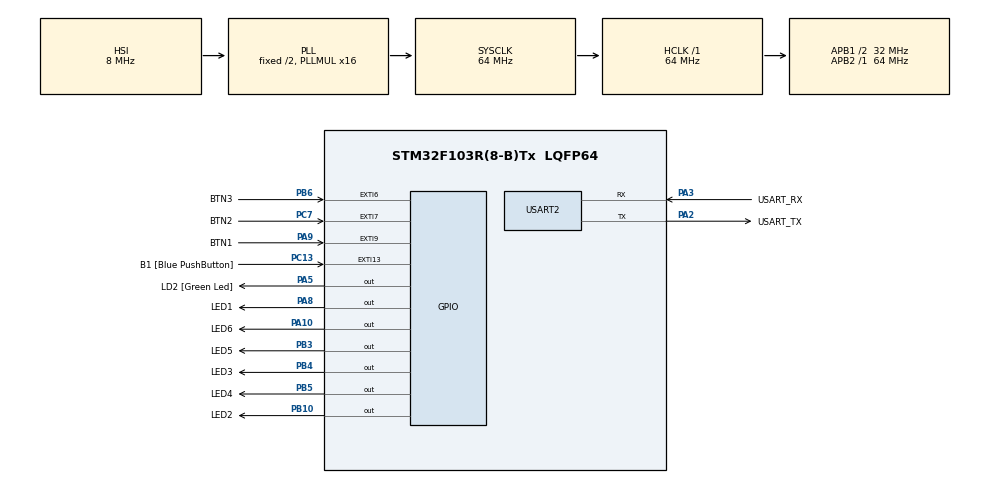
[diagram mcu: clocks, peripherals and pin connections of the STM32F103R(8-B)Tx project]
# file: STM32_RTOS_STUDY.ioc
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FREERTOS.Tasks01=defaultTask,24,128,StartDefaultTask,Default,NULL,Dynamic,NULL,NULL
FREERTOS.configTOTAL_HEAP_SIZE=10240
Mcu.Family=STM32F1
Mcu.Name=STM32F103R(8-B)Tx
Mcu.Package=LQFP64
NVIC.EXTI15_10_IRQn=true\:5\:0\:false\:false\:true\:true\:true\:true\:true
NVIC.EXTI9_5_IRQn=true\:5\:0\:false\:false\:true\:true\:true\:true\:true
NVIC.PriorityGroup=NVIC_PRIORITYGROUP_4
PA10.GPIO_Label=LED6
PA10.Signal=GPIO_Output
PA13.GPIO_Label=TMS
PA13.Mode=Serial_Wire
PA13.Signal=SYS_JTMS-SWDIO
PA14.GPIO_Label=TCK
PA14.Mode=Serial_Wire
PA14.Signal=SYS_JTCK-SWCLK
PA2.GPIO_Label=USART_TX
PA2.GPIO_Mode=GPIO_MODE_AF_PP
PA2.GPIO_PuPd=GPIO_NOPULL
PA2.GPIO_Speed=GPIO_SPEED_FREQ_LOW
PA2.Mode=Asynchronous
PA2.Signal=USART2_TX
PA3.GPIO_Label=USART_RX
PA3.GPIO_Mode=GPIO_MODE_AF_PP
PA3.GPIO_PuPd=GPIO_NOPULL
PA3.GPIO_Speed=GPIO_SPEED_FREQ_LOW
PA3.Mode=Asynchronous
PA3.Signal=USART2_RX
PA5.GPIO_Label=LD2 [Green Led]
PA5.GPIO_ModeDefaultOutputPP=GPIO_MODE_OUTPUT_PP
PA5.GPIO_PuPd=GPIO_NOPULL
PA5.GPIO_Speed=GPIO_SPEED_FREQ_LOW
PA5.Signal=GPIO_Output
PA8.GPIO_Label=LED1
PA8.PinState=GPIO_PIN_RESET
PA8.Signal=GPIO_Output
PA9.GPIO_Label=BTN1
PA9.GPIO_ModeDefaultEXTI=GPIO_MODE_IT_RISING
PA9.GPIO_PuPd=GPIO_PULLUP
PA9.Signal=GPXTI9
PB10.GPIO_Label=LED2
PB10.Signal=GPIO_Output
PB3.GPIO_Label=LED5
PB3.Signal=GPIO_Output
PB4.GPIO_Label=LED3
PB4.Signal=GPIO_Output
PB5.GPIO_Label=LED4
PB5.Signal=GPIO_Output
PB6.GPIO_Label=BTN3
PB6.GPIO_ModeDefaultEXTI=GPIO_MODE_IT_RISING
PB6.GPIO_PuPd=GPIO_PULLUP
PB6.Signal=GPXTI6
PC13-TAMPER-RTC.GPIO_Label=B1 [Blue PushButton]
PC13-TAMPER-RTC.GPIO_PuPd=GPIO_NOPULL
PC13-TAMPER-RTC.Signal=GPXTI13
PC14-OSC32_IN.Mode=LSE-External-Oscillator
PC14-OSC32_IN.Signal=RCC_OSC32_IN
PC15-OSC32_OUT.Mode=LSE-External-Oscillator
PC15-OSC32_OUT.Signal=RCC_OSC32_OUT
PC7.GPIO_Label=BTN2
PC7.GPIO_ModeDefaultEXTI=GPIO_MODE_IT_RISING
PC7.GPIO_PuPd=GPIO_PULLUP
PC7.Signal=GPXTI7
PD0-OSC_IN.Mode=HSE-External-Clock-Source
PD0-OSC_IN.Signal=RCC_OSC_IN
PD1-OSC_OUT.Mode=HSE-External-Clock-Source
PD1-OSC_OUT.Signal=RCC_OSC_OUT
ProjectManager.HeapSize=0x200
ProjectManager.StackSize=0x400
ProjectManager.TargetToolchain=STM32CubeIDE
RCC.AHBFreq_Value=64000000
RCC.APB1CLKDivider=RCC_HCLK_DIV2
RCC.APB1Freq_Value=32000000
RCC.APB1TimFreq_Value=64000000
RCC.APB2Freq_Value=64000000
RCC.APB2TimFreq_Value=64000000
RCC.HCLKFreq_Value=64000000
RCC.PLLMUL=RCC_PLL_MUL16
RCC.RTCClockSelection=RCC_RTCCLKSOURCE_LSE
RCC.SYSCLKFreq_VALUE=64000000
RCC.SYSCLKSource=RCC_SYSCLKSOURCE_PLLCLK
RCC.USBFreq_Value=64000000
USART2.VirtualMode=VM_ASYNC
VP_FREERTOS_VS_CMSIS_V2.Mode=CMSIS_V2
board=NUCLEO-F103RB

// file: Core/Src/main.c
/* USER CODE BEGIN Header */
/**
  ******************************************************************************
  * @file           : main.c
  * @brief          : Main program body
  ******************************************************************************
  * @attention
  *
  * Copyright (c) 2025 STMicroelectronics.
  * All rights reserved.
  *
  * This software is licensed under terms that can be found in the LICENSE file
  * in the root directory of this software component.
  * If no LICENSE file comes with this software, it is provided AS-IS.
  *
  ******************************************************************************
  */
/* USER CODE END Header */
#include "main.h"
#include "cmsis_os.h"

/* USER CODE BEGIN Includes */
#include <stdio.h>
/* USER CODE END Includes */

UART_HandleTypeDef huart2;

/* Definitions for defaultTask */
osThreadId_t defaultTaskHandle;
const osThreadAttr_t defaultTask_attributes = {
  .name = "defaultTask",
  .stack_size = 128 * 4,
  .priority = (osPriority_t) osPriorityNormal,
};

void SystemClock_Config(void);
static void MX_GPIO_Init(void);
static void MX_USART2_UART_Init(void);
void StartDefaultTask(void *argument);

/* USER CODE BEGIN PFP */
void myTask();
/* USER CODE END PFP */

/* USER CODE BEGIN 0 */
int __io_putchar(int ch)
{
 if ( ch == '\n' )
   HAL_UART_Transmit(&huart2, (uint8_t*)&"\r", 1, HAL_MAX_DELAY);
 HAL_UART_Transmit(&huart2, (uint8_t*)&ch, 1, HAL_MAX_DELAY);
 return ch;
}
/* USER CODE END 0 */

int main(void)
{

  /* MCU Configuration--------------------------------------------------------*/

  /* Reset of all peripherals, Initializes the Flash interface and the Systick. */
  HAL_Init();

  /* Configure the system clock */
  SystemClock_Config();

  /* Initialize all configured peripherals */
  MX_GPIO_Init();
  MX_USART2_UART_Init();

  /* Init scheduler */
  osKernelInitialize();

  /* Create the thread(s) */
  /* creation of defaultTask */
  defaultTaskHandle = osThreadNew(StartDefaultTask, NULL, &defaultTask_attributes);

  /* USER CODE BEGIN RTOS_THREADS */
  myTask();
  /* add threads, ... */
  /* USER CODE END RTOS_THREADS */

  /* Start scheduler */
  osKernelStart();

  /* We should never get here as control is now taken by the scheduler */
  /* Infinite loop */
  while (1)
  {

  }
}

void SystemClock_Config(void)
{
  RCC_OscInitTypeDef RCC_OscInitStruct = {0};
  RCC_ClkInitTypeDef RCC_ClkInitStruct = {0};

  /** Initializes the RCC Oscillators according to the specified parameters
  * in the RCC_OscInitTypeDef structure.
  */
  RCC_OscInitStruct.OscillatorType = RCC_OSCILLATORTYPE_HSI;
  RCC_OscInitStruct.HSIState = RCC_HSI_ON;
  RCC_OscInitStruct.HSICalibrationValue = RCC_HSICALIBRATION_DEFAULT;
  RCC_OscInitStruct.PLL.PLLState = RCC_PLL_ON;
  RCC_OscInitStruct.PLL.PLLSource = RCC_PLLSOURCE_HSI_DIV2;
  RCC_OscInitStruct.PLL.PLLMUL = RCC_PLL_MUL16;
  if (HAL_RCC_OscConfig(&RCC_OscInitStruct) != HAL_OK)
  {
    Error_Handler();
  }

  /** Initializes the CPU, AHB and APB buses clocks
  */
  RCC_ClkInitStruct.ClockType = RCC_CLOCKTYPE_HCLK|RCC_CLOCKTYPE_SYSCLK
                              |RCC_CLOCKTYPE_PCLK1|RCC_CLOCKTYPE_PCLK2;
  RCC_ClkInitStruct.SYSCLKSource = RCC_SYSCLKSOURCE_PLLCLK;
  RCC_ClkInitStruct.AHBCLKDivider = RCC_SYSCLK_DIV1;
  RCC_ClkInitStruct.APB1CLKDivider = RCC_HCLK_DIV2;
  RCC_ClkInitStruct.APB2CLKDivider = RCC_HCLK_DIV1;

  if (HAL_RCC_ClockConfig(&RCC_ClkInitStruct, FLASH_LATENCY_2) != HAL_OK)
  {
    Error_Handler();
  }
}

static void MX_USART2_UART_Init(void)
{

  huart2.Instance = USART2;
  huart2.Init.BaudRate = 115200;
  huart2.Init.WordLength = UART_WORDLENGTH_8B;
  huart2.Init.StopBits = UART_STOPBITS_1;
  huart2.Init.Parity = UART_PARITY_NONE;
  huart2.Init.Mode = UART_MODE_TX_RX;
  huart2.Init.HwFlowCtl = UART_HWCONTROL_NONE;
  huart2.Init.OverSampling = UART_OVERSAMPLING_16;
  if (HAL_UART_Init(&huart2) != HAL_OK)
  {
    Error_Handler();
  }

}

static void MX_GPIO_Init(void)
{
  GPIO_InitTypeDef GPIO_InitStruct = {0};

  /* GPIO Ports Clock Enable */
  __HAL_RCC_GPIOC_CLK_ENABLE();
  __HAL_RCC_GPIOD_CLK_ENABLE();
  __HAL_RCC_GPIOA_CLK_ENABLE();
  __HAL_RCC_GPIOB_CLK_ENABLE();

  /*Configure GPIO pin Output Level */
  HAL_GPIO_WritePin(GPIOA, LD2_Pin|LED1_Pin|LED6_Pin, GPIO_PIN_RESET);

  /*Configure GPIO pin Output Level */
  HAL_GPIO_WritePin(GPIOB, LED2_Pin|LED5_Pin|LED3_Pin|LED4_Pin, GPIO_PIN_RESET);

  /*Configure GPIO pin : B1_Pin */
  GPIO_InitStruct.Pin = B1_Pin;
  GPIO_InitStruct.Mode = GPIO_MODE_IT_RISING;
  GPIO_InitStruct.Pull = GPIO_NOPULL;
  HAL_GPIO_Init(B1_GPIO_Port, &GPIO_InitStruct);

  /*Configure GPIO pins : LD2_Pin LED1_Pin LED6_Pin */
  GPIO_InitStruct.Pin = LD2_Pin|LED1_Pin|LED6_Pin;
  GPIO_InitStruct.Mode = GPIO_MODE_OUTPUT_PP;
  GPIO_InitStruct.Pull = GPIO_NOPULL;
  GPIO_InitStruct.Speed = GPIO_SPEED_FREQ_LOW;
  HAL_GPIO_Init(GPIOA, &GPIO_InitStruct);

  /*Configure GPIO pins : LED2_Pin LED5_Pin LED3_Pin LED4_Pin */
  GPIO_InitStruct.Pin = LED2_Pin|LED5_Pin|LED3_Pin|LED4_Pin;
  GPIO_InitStruct.Mode = GPIO_MODE_OUTPUT_PP;
  GPIO_InitStruct.Pull = GPIO_NOPULL;
  GPIO_InitStruct.Speed = GPIO_SPEED_FREQ_LOW;
  HAL_GPIO_Init(GPIOB, &GPIO_InitStruct);

  /*Configure GPIO pin : BTN2_Pin */
  GPIO_InitStruct.Pin = BTN2_Pin;
  GPIO_InitStruct.Mode = GPIO_MODE_IT_RISING;
  GPIO_InitStruct.Pull = GPIO_PULLUP;
  HAL_GPIO_Init(BTN2_GPIO_Port, &GPIO_InitStruct);

  /*Configure GPIO pin : BTN1_Pin */
  GPIO_InitStruct.Pin = BTN1_Pin;
  GPIO_InitStruct.Mode = GPIO_MODE_IT_RISING;
  GPIO_InitStruct.Pull = GPIO_PULLUP;
  HAL_GPIO_Init(BTN1_GPIO_Port, &GPIO_InitStruct);

  /*Configure GPIO pin : BTN3_Pin */
  GPIO_InitStruct.Pin = BTN3_Pin;
  GPIO_InitStruct.Mode = GPIO_MODE_IT_RISING;
  GPIO_InitStruct.Pull = GPIO_PULLUP;
  HAL_GPIO_Init(BTN3_GPIO_Port, &GPIO_InitStruct);

  /* EXTI interrupt init*/
  HAL_NVIC_SetPriority(EXTI9_5_IRQn, 5, 0);
  HAL_NVIC_EnableIRQ(EXTI9_5_IRQn);

  HAL_NVIC_SetPriority(EXTI15_10_IRQn, 5, 0);
  HAL_NVIC_EnableIRQ(EXTI15_10_IRQn);

}

void StartDefaultTask(void *argument)
{
  for(;;)
  {
    osDelay(1);
  }
}

void Error_Handler(void)
{
  __disable_irq();
  while (1)
  {
  }
}
